AUTOSAR XML (schema 00046)
package /VehicleProject
  system System
package /NM
  nm config NmConfig: can-nm-cluster-coupling=coupled-cluster=[DBCNetWork_CAN, DBCNetWork_Can0_CAN]
    can nm cluster DBCNetWork_CAN: communication-cluster=DBCNetWork, nm-channel-id=0, nm-network-timeout=2, nm-user-data-length=6, nm-wait-bus-sleep-time=2
      can nm node XB_SUP_A: controller=CT_DBCNetWork, nm-if-ecu=XB_SUP_A_CAN, nm-node-id=1, rx-nm-pdu=Meg_NmRx_oDBCNetWork, tx-nm-pdu=Meg_NmTx_oDBCNetWork, nm-range-config={lower-can-id=1536, upper-can-id=1791}
      can nm node XB_SUP_B: nm-if-ecu=XB_SUP_B_CAN, nm-node-id=0, rx-nm-pdu=Meg_NmTx_oDBCNetWork, tx-nm-pdu=Meg_NmRx_oDBCNetWork, nm-range-config={lower-can-id=1536, upper-can-id=1791}
      can nm node XB_SUP_C: nm-if-ecu=XB_SUP_C_CAN, nm-node-id=0, nm-passive-mode-enabled=true, nm-range-config={lower-can-id=1536, upper-can-id=1791}
    can nm cluster DBCNetWork_Can0_CAN: communication-cluster=DBCNetWork_Can0, nm-channel-id=1, nm-network-timeout=2, nm-user-data-length=6, nm-wait-bus-sleep-time=2
      can nm node Host: nm-if-ecu=Host_CAN, nm-node-id=0, nm-passive-mode-enabled=true, nm-range-config={lower-can-id=1536, upper-can-id=1791}
      can nm node XB_SUP_A: controller=CT_DBCNetWork_Can0, nm-if-ecu=XB_SUP_A_CAN, nm-node-id=1, nm-passive-mode-enabled=true, nm-range-config={lower-can-id=1536, upper-can-id=1791}
    nm-if-ecus:
      4 x nm ecu, all with nm-node-id-enabled=true, nm-user-data-enabled=true:
        Host_CAN: nm-passive-mode-enabled=true
        XB_SUP_A_CAN: ecu-instance=XB_SUP_A, nm-passive-mode-enabled=true
        XB_SUP_B_CAN
        XB_SUP_C_CAN: nm-passive-mode-enabled=true
package /TP
  can tp config DBCNetWork_CAN: communication-cluster=DBCNetWork, can-tp-ecu{cycle-time-main-function=0.005, ecu-instance=XB_SUP_A}
    can tp channel TPCH: channel-id=0, channel-mode=FULL-DUPLEX-MODE
    can-tp-connection addressing-format=STANDARD, can-tp-channel=TPCH, data-pdu=Meg_FunDiag_Tp_oDBCNetWork, receiver=TN_XB_SUP_A, ta-type=FUNCTIONAL, tp-sdu=Meg_FunDiag_oDBCNetWork, transmitter=TN_XB_SUP_B:
      ident Meg_FunDiag_oTN_XB_SUP_B
    can-tp-connection addressing-format=STANDARD, can-tp-channel=TPCH, data-pdu=Meg_PhyDiag_Tp_oDBCNetWork, flow-control-pdu=Meg_ResDiag_Tp_oDBCNetWork, receiver=TN_XB_SUP_A, ta-type=PHYSICAL, tp-sdu=Meg_PhyDiag_oDBCNetWork, transmitter=TN_XB_SUP_B:
      ident Meg_PhyDiag_oTN_XB_SUP_A
    can-tp-connection addressing-format=STANDARD, can-tp-channel=TPCH, data-pdu=Meg_ResDiag_Tp_oDBCNetWork, flow-control-pdu=Meg_PhyDiag_Tp_oDBCNetWork, receiver=TN_XB_SUP_B, ta-type=PHYSICAL, tp-sdu=Meg_ResDiag_oDBCNetWork, transmitter=TN_XB_SUP_A:
      ident Meg_ResDiag_oTN_XB_SUP_A
    can tp node TN_XB_SUP_A: connector=CN_DBCNetWork
    can tp node TN_XB_SUP_B
package /Cluster
  can cluster DBCNetWork: baudrate=500000, protocol-name=CAN  # Vector_XWXZ_CAN1
    can physical channel CHNL: comm-connectors=CN_DBCNetWork
      frame Meg_FunDiag_oDBCNetWork: id 0x7DF, to XB_SUP_A, frame-length=8, can-addressing-mode=STANDARD
        n pdu Meg_FunDiag_Tp_oDBCNetWork: length=8
      frame Meg_NmRx_oDBCNetWork: id 0x600, to XB_SUP_A, frame-length=8, can-addressing-mode=STANDARD
        nm pdu Meg_NmRx_oDBCNetWork: length=8, unused-bit-pattern=0
      frame Meg_NmTx_oDBCNetWork: id 0x601, from XB_SUP_A, frame-length=8, can-addressing-mode=STANDARD
        nm pdu Meg_NmTx_oDBCNetWork: length=8, unused-bit-pattern=0
      frame Meg_PhyDiag_oDBCNetWork: id 0x701, to XB_SUP_A, frame-length=8, can-addressing-mode=STANDARD
        n pdu Meg_PhyDiag_Tp_oDBCNetWork: length=8
      frame Meg_ResDiag_oDBCNetWork: id 0x751, from XB_SUP_A, frame-length=8, can-addressing-mode=STANDARD
        n pdu Meg_ResDiag_Tp_oDBCNetWork: length=8
      frame Route_Can0ToCan1_100ms_oDBCNetWork: id 0x569, from XB_SUP_A, frame-length=8, can-addressing-mode=STANDARD
        user defined pdu Route_Can0ToCan1_100ms_oDBCNetWork: length=8
      frame Route_Can1ToCan0_100ms_oDBCNetWork: id 0x3AD, to XB_SUP_A, frame-length=8, can-addressing-mode=STANDARD
        user defined pdu Route_Can1ToCan0_100ms_oDBCNetWork: length=8
      frame SupA_Angle_oDBCNetWork: id 0x113, from XB_SUP_A, frame-length=8, can-addressing-mode=STANDARD
        pdu SupA_Angle_oDBCNetWork: length=8, minimum-delay=0, transmission-mode-false-timing=cyclic-timing={time-offset=0, time-period=0.01}, transmission-mode-true-timing=cyclic-timing={time-offset=0, time-period=0.01}, unused-bit-pattern=0
          signal AAA_Angle_oSupA_Angle_oDBCNetWork: start 5, 6 bit, big-endian, init-value=20, base-type=uint8, compu-method=CM_AAA_Angle, unit=U_o, transfer-property=PENDING
          mapping SG_Sig_Grp_0x113: i-signal-group=SG_Sig_Grp_0x113_oSupA_Angle_oDBCNetWork, transfer-property=PENDING
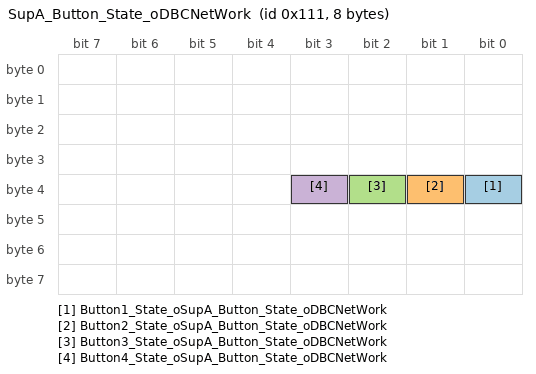
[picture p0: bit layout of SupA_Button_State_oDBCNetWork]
      frame SupA_Button_State_oDBCNetWork: id 0x111, from XB_SUP_A, frame-length=8, can-addressing-mode=STANDARD
        pdu SupA_Button_State_oDBCNetWork: length=8, minimum-delay=0, transmission-mode-false-timing=cyclic-timing={time-offset=0, time-period=0.01}, transmission-mode-true-timing=cyclic-timing={time-offset=0, time-period=0.01}, unused-bit-pattern=0
          signal Button1_State_oSupA_Button_State_oDBCNetWork: start 32, 1 bit, big-endian, init-value=0, base-type=boolean, compu-method=CM_Button1_State, transfer-property=PENDING
          signal Button2_State_oSupA_Button_State_oDBCNetWork: start 33, 1 bit, big-endian, init-value=0, base-type=boolean, compu-method=CM_Button2_State, transfer-property=PENDING
          signal Button3_State_oSupA_Button_State_oDBCNetWork: start 34, 1 bit, big-endian, init-value=0, base-type=boolean, compu-method=CM_Button3_State, transfer-property=PENDING
          signal Button4_State_oSupA_Button_State_oDBCNetWork: start 35, 1 bit, big-endian, init-value=0, base-type=boolean, compu-method=CM_Button4_State, transfer-property=PENDING
          mapping SG_Sig_Grp_0x111: i-signal-group=SG_Sig_Grp_0x111_oSupA_Button_State_oDBCNetWork, transfer-property=PENDING
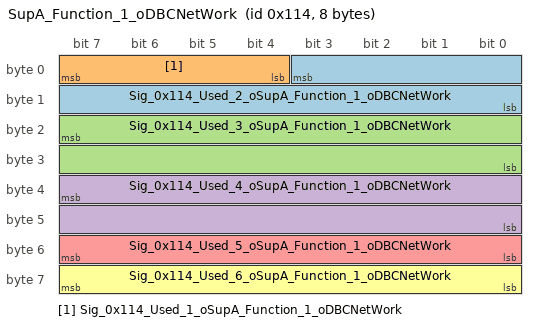
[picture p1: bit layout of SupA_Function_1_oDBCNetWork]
      frame SupA_Function_1_oDBCNetWork: id 0x114, from XB_SUP_A, frame-length=8, can-addressing-mode=STANDARD
        pdu SupA_Function_1_oDBCNetWork: length=8, minimum-delay=0, transmission-mode-false-timing={cyclic-timing={time-offset=0, time-period=0}, event-controlled-timing={number-of-repetitions=4, repetition-period=0.02}}, transmission-mode-true-timing={cyclic-timing={time-offset=0, time-period=0}, event-controlled-timing={number-of-repetitions=4, repetition-period=0.02}}, unused-bit-pattern=0
          signal Sig_0x114_Used_2_oSupA_Function_1_oDBCNetWork: start 3, 12 bit, big-endian, init-value=0, base-type=uint16, compu-method=CM_Sig_0x114_Used_2, data-constr=DC_Sig_0x114_Used_2, transfer-property=PENDING
          signal Sig_0x114_Used_1_oSupA_Function_1_oDBCNetWork: start 7, 4 bit, big-endian, init-value=0, base-type=uint8, compu-method=CM_Sig_0x114_Used_1, data-constr=DC_Sig_0x114_Used_1, transfer-property=PENDING
          signal Sig_0x114_Used_3_oSupA_Function_1_oDBCNetWork: start 23, 16 bit, big-endian, init-value=0, base-type=uint16, compu-method=CM_Sig_0x114_Used_3, data-constr=DC_Sig_0x114_Used_3, transfer-property=PENDING
          signal Sig_0x114_Used_4_oSupA_Function_1_oDBCNetWork: start 39, 16 bit, big-endian, init-value=0, base-type=uint16, compu-method=CM_Sig_0x114_Used_4, data-constr=DC_Sig_0x114_Used_4, transfer-property=PENDING
          signal Sig_0x114_Used_5_oSupA_Function_1_oDBCNetWork: start 55, 8 bit, big-endian, init-value=0, base-type=uint8, compu-method=CM_Sig_0x114_Used_5, data-constr=DC_Sig_0x114_Used_5, transfer-property=PENDING
          signal Sig_0x114_Used_6_oSupA_Function_1_oDBCNetWork: start 63, 8 bit, big-endian, init-value=0, base-type=uint8, compu-method=CM_Sig_0x114_Used_6, data-constr=DC_Sig_0x114_Used_6, transfer-property=TRIGGERED
          mapping SG_Sig_Grp_0x114: i-signal-group=SG_Sig_Grp_0x114_oSupA_Function_1_oDBCNetWork, transfer-property=PENDING
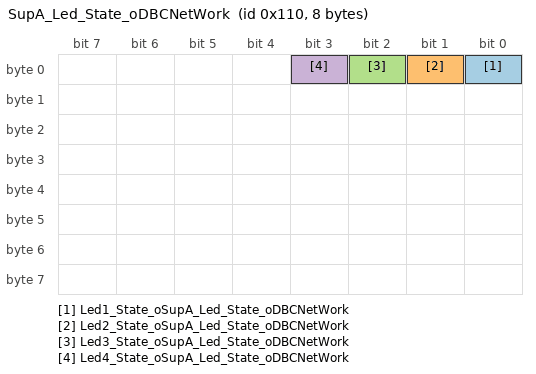
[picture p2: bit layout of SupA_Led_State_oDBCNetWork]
      frame SupA_Led_State_oDBCNetWork: id 0x110, from XB_SUP_A, frame-length=8, can-addressing-mode=STANDARD
        pdu SupA_Led_State_oDBCNetWork: length=8, minimum-delay=0, transmission-mode-false-timing=cyclic-timing={time-offset=0, time-period=0.01}, transmission-mode-true-timing=cyclic-timing={time-offset=0, time-period=0.01}, unused-bit-pattern=0
          signal Led1_State_oSupA_Led_State_oDBCNetWork: start 0, 1 bit, big-endian, init-value=0, base-type=boolean, compu-method=CM_Led1_State, transfer-property=PENDING
          signal Led2_State_oSupA_Led_State_oDBCNetWork: start 1, 1 bit, big-endian, init-value=0, base-type=boolean, compu-method=CM_Led2_State, transfer-property=PENDING
          signal Led3_State_oSupA_Led_State_oDBCNetWork: start 2, 1 bit, big-endian, init-value=0, base-type=boolean, compu-method=CM_Led3_State, transfer-property=PENDING
          signal Led4_State_oSupA_Led_State_oDBCNetWork: start 3, 1 bit, big-endian, init-value=0, base-type=boolean, compu-method=CM_Led4_State, transfer-property=PENDING
          mapping SG_Sig_Grp_0x110: i-signal-group=SG_Sig_Grp_0x110_oSupA_Led_State_oDBCNetWork, transfer-property=PENDING
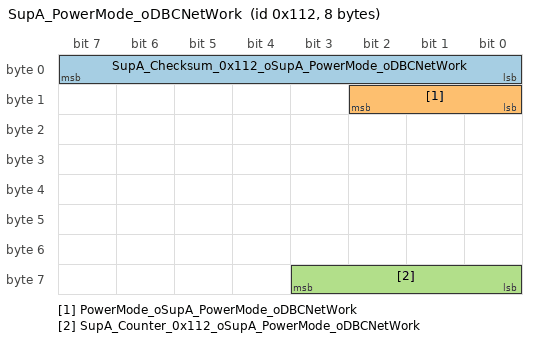
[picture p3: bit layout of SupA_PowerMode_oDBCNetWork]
      frame SupA_PowerMode_oDBCNetWork: id 0x112, from XB_SUP_A, frame-length=8, can-addressing-mode=STANDARD
        pdu SupA_PowerMode_oDBCNetWork: length=8, minimum-delay=0, transmission-mode-false-timing=cyclic-timing={time-offset=0, time-period=0.2}, transmission-mode-true-timing=cyclic-timing={time-offset=0, time-period=0.2}, unused-bit-pattern=0
          signal SupA_Checksum_0x112_oSupA_PowerMode_oDBCNetWork: start 7, 8 bit, big-endian, init-value=0, base-type=uint8, compu-method=CM_SupA_Checksum_0x112, data-constr=DC_SupA_Checksum_0x112, transfer-property=PENDING
          signal PowerMode_oSupA_PowerMode_oDBCNetWork: start 10, 3 bit, big-endian, init-value=0, base-type=uint8, compu-method=CM_PowerMode, data-constr=DC_PowerMode, transfer-property=PENDING
          signal SupA_Counter_0x112_oSupA_PowerMode_oDBCNetWork: start 59, 4 bit, big-endian, init-value=0, base-type=uint8, compu-method=CM_SupA_Counter_0x112, data-constr=DC_SupA_Counter_0x112, transfer-property=PENDING
          mapping SG_Sig_Grp_0x112: i-signal-group=SG_Sig_Grp_0x112_oSupA_PowerMode_oDBCNetWork, transfer-property=PENDING
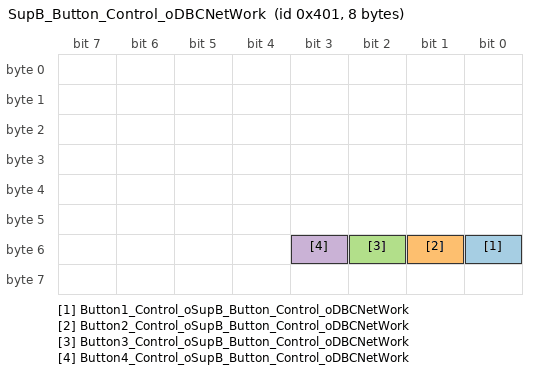
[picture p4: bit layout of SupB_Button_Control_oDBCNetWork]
      frame SupB_Button_Control_oDBCNetWork: id 0x401, to XB_SUP_A, frame-length=8, can-addressing-mode=STANDARD
        pdu SupB_Button_Control_oDBCNetWork: length=8, minimum-delay=0, transmission-mode-false-timing=cyclic-timing={time-offset=0, time-period=0.01}, transmission-mode-true-timing=cyclic-timing={time-offset=0, time-period=0.01}, unused-bit-pattern=0
          signal Button1_Control_oSupB_Button_Control_oDBCNetWork: start 48, 1 bit, big-endian, init-value=0, base-type=boolean, compu-method=CM_Button1_Control, transfer-property=PENDING, to XB_SUP_A
          signal Button2_Control_oSupB_Button_Control_oDBCNetWork: start 49, 1 bit, big-endian, init-value=0, base-type=boolean, compu-method=CM_Button2_Control, transfer-property=PENDING, to XB_SUP_A
          signal Button3_Control_oSupB_Button_Control_oDBCNetWork: start 50, 1 bit, big-endian, init-value=0, base-type=boolean, compu-method=CM_Button3_Control, transfer-property=PENDING, to XB_SUP_A
          signal Button4_Control_oSupB_Button_Control_oDBCNetWork: start 51, 1 bit, big-endian, init-value=0, base-type=boolean, compu-method=CM_Button4_Control, transfer-property=PENDING, to XB_SUP_A
          mapping SG_Sig_Grp_0x401: i-signal-group=SG_Sig_Grp_0x401_oSupB_Button_Control_oDBCNetWork, transfer-property=PENDING
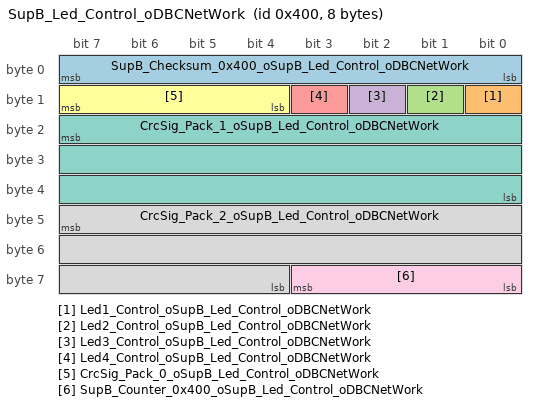
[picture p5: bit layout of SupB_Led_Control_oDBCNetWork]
      frame SupB_Led_Control_oDBCNetWork: id 0x400, to XB_SUP_A, frame-length=8, can-addressing-mode=STANDARD
        pdu SupB_Led_Control_oDBCNetWork: length=8, minimum-delay=0, transmission-mode-false-timing=cyclic-timing={time-offset=0, time-period=0.01}, transmission-mode-true-timing=cyclic-timing={time-offset=0, time-period=0.01}, unused-bit-pattern=0
          signal SupB_Checksum_0x400_oSupB_Led_Control_oDBCNetWork: start 7, 8 bit, big-endian, init-value=0, base-type=uint8, compu-method=CM_SupB_Checksum_0x400, data-constr=DC_SupB_Checksum_0x400, transfer-property=PENDING, to XB_SUP_A
          signal Led1_Control_oSupB_Led_Control_oDBCNetWork: start 8, 1 bit, big-endian, init-value=1, base-type=boolean, compu-method=CM_Led1_Control, data-constr=DC_Led1_Control, transfer-property=PENDING, to XB_SUP_A
          signal Led2_Control_oSupB_Led_Control_oDBCNetWork: start 9, 1 bit, big-endian, init-value=1, base-type=boolean, compu-method=CM_Led2_Control, data-constr=DC_Led2_Control, transfer-property=PENDING, to XB_SUP_A
          signal Led3_Control_oSupB_Led_Control_oDBCNetWork: start 10, 1 bit, big-endian, init-value=1, base-type=boolean, compu-method=CM_Led3_Control, data-constr=DC_Led3_Control, transfer-property=PENDING, to XB_SUP_A
          signal Led4_Control_oSupB_Led_Control_oDBCNetWork: start 11, 1 bit, big-endian, init-value=1, base-type=boolean, compu-method=CM_Led4_Control, data-constr=DC_Led4_Control, transfer-property=PENDING, to XB_SUP_A
          signal CrcSig_Pack_0_oSupB_Led_Control_oDBCNetWork: start 15, 4 bit, big-endian, init-value=0, base-type=uint8, compu-method=CM_CrcSig_Pack_0, data-constr=DC_CrcSig_Pack_0, transfer-property=PENDING, to XB_SUP_A
          signal CrcSig_Pack_1_oSupB_Led_Control_oDBCNetWork: start 23, 24 bit, big-endian, init-value=0, base-type=uint32, compu-method=CM_CrcSig_Pack_1, data-constr=DC_CrcSig_Pack_1, transfer-property=PENDING, to XB_SUP_A
          signal CrcSig_Pack_2_oSupB_Led_Control_oDBCNetWork: start 47, 20 bit, big-endian, init-value=0, base-type=uint32, compu-method=CM_CrcSig_Pack_2, data-constr=DC_CrcSig_Pack_2, transfer-property=PENDING, to XB_SUP_A
          signal SupB_Counter_0x400_oSupB_Led_Control_oDBCNetWork: start 59, 4 bit, big-endian, init-value=0, base-type=uint8, compu-method=CM_SupB_Counter_0x400, data-constr=DC_SupB_Counter_0x400, transfer-property=PENDING, to XB_SUP_A
          mapping SG_Sig_Grp_0x400: i-signal-group=SG_Sig_Grp_0x400_oSupB_Led_Control_oDBCNetWork, transfer-property=PENDING
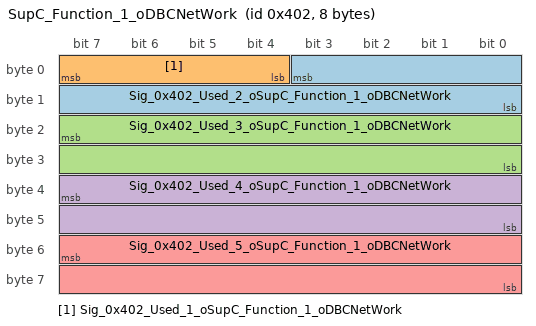
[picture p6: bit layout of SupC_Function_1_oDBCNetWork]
      frame SupC_Function_1_oDBCNetWork: id 0x402, to XB_SUP_A, frame-length=8, can-addressing-mode=STANDARD
        pdu SupC_Function_1_oDBCNetWork: length=8, minimum-delay=0, transmission-mode-false-timing=cyclic-timing={time-offset=0, time-period=0.01}, transmission-mode-true-timing=cyclic-timing={time-offset=0, time-period=0.01}, unused-bit-pattern=0
          signal Sig_0x402_Used_2_oSupC_Function_1_oDBCNetWork: start 3, 12 bit, big-endian, init-value=0, base-type=uint16, compu-method=CM_Sig_0x402_Used_2, data-constr=DC_Sig_0x402_Used_2, transfer-property=PENDING, to XB_SUP_A
          signal Sig_0x402_Used_1_oSupC_Function_1_oDBCNetWork: start 7, 4 bit, big-endian, init-value=0, base-type=uint8, compu-method=CM_Sig_0x402_Used_1, data-constr=DC_Sig_0x402_Used_1, transfer-property=PENDING, to XB_SUP_A
          signal Sig_0x402_Used_3_oSupC_Function_1_oDBCNetWork: start 23, 16 bit, big-endian, init-value=0, base-type=uint16, compu-method=CM_Sig_0x402_Used_3, data-constr=DC_Sig_0x402_Used_3, transfer-property=PENDING, to XB_SUP_A
          signal Sig_0x402_Used_4_oSupC_Function_1_oDBCNetWork: start 39, 16 bit, big-endian, init-value=0, base-type=uint16, compu-method=CM_Sig_0x402_Used_4, data-constr=DC_Sig_0x402_Used_4, transfer-property=PENDING, to XB_SUP_A
          signal Sig_0x402_Used_5_oSupC_Function_1_oDBCNetWork: start 55, 16 bit, big-endian, init-value=0, base-type=uint16, compu-method=CM_Sig_0x402_Used_5, data-constr=DC_Sig_0x402_Used_5, transfer-property=PENDING, to XB_SUP_A
          mapping SG_Sig_Grp_0x402: i-signal-group=SG_Sig_Grp_0x402_oSupC_Function_1_oDBCNetWork, transfer-property=PENDING
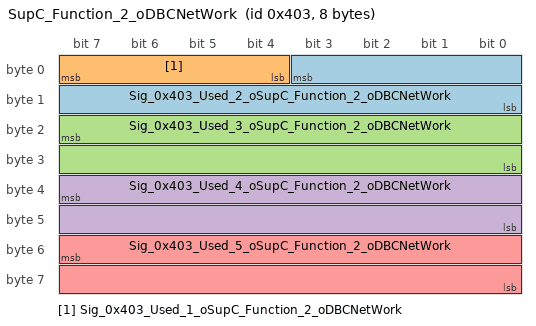
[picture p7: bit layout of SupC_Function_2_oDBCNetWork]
      frame SupC_Function_2_oDBCNetWork: id 0x403, to XB_SUP_A, frame-length=8, can-addressing-mode=STANDARD
        pdu SupC_Function_2_oDBCNetWork: length=8, minimum-delay=0, transmission-mode-false-timing=cyclic-timing={time-offset=0, time-period=0.01}, transmission-mode-true-timing=cyclic-timing={time-offset=0, time-period=0.01}, unused-bit-pattern=0
          signal Sig_0x403_Used_2_oSupC_Function_2_oDBCNetWork: start 3, 12 bit, big-endian, init-value=0, base-type=uint16, compu-method=CM_Sig_0x403_Used_2, data-constr=DC_Sig_0x403_Used_2, transfer-property=PENDING, to XB_SUP_A
          signal Sig_0x403_Used_1_oSupC_Function_2_oDBCNetWork: start 7, 4 bit, big-endian, init-value=0, base-type=uint8, compu-method=CM_Sig_0x403_Used_1, data-constr=DC_Sig_0x403_Used_1, transfer-property=PENDING, to XB_SUP_A
          signal Sig_0x403_Used_3_oSupC_Function_2_oDBCNetWork: start 23, 16 bit, big-endian, init-value=0, base-type=uint16, compu-method=CM_Sig_0x403_Used_3, data-constr=DC_Sig_0x403_Used_3, transfer-property=PENDING, to XB_SUP_A
          signal Sig_0x403_Used_4_oSupC_Function_2_oDBCNetWork: start 39, 16 bit, big-endian, init-value=0, base-type=uint16, compu-method=CM_Sig_0x403_Used_4, data-constr=DC_Sig_0x403_Used_4, transfer-property=PENDING, to XB_SUP_A
          signal Sig_0x403_Used_5_oSupC_Function_2_oDBCNetWork: start 55, 16 bit, big-endian, init-value=0, base-type=uint16, compu-method=CM_Sig_0x403_Used_5, data-constr=DC_Sig_0x403_Used_5, transfer-property=PENDING, to XB_SUP_A
          mapping SG_Sig_Grp_0x403: i-signal-group=SG_Sig_Grp_0x403_oSupC_Function_2_oDBCNetWork, transfer-property=PENDING
      pdu triggering PT_Meg_FunDiag: pdu=Meg_FunDiag_oDBCNetWork, to XB_SUP_A
      pdu triggering PT_Meg_PhyDiag: pdu=Meg_PhyDiag_oDBCNetWork, to XB_SUP_A
      pdu triggering PT_Meg_ResDiag: pdu=Meg_ResDiag_oDBCNetWork, from XB_SUP_A
  can cluster DBCNetWork_Can0: baudrate=500000, protocol-name=CAN  # Vector_XWXZ_CAN0
    can physical channel CHNL: comm-connectors=CN_DBCNetWork_Can0
      frame Ecu_Receive_Msg_oDBCNetWork_Can0: id 0x200, to XB_SUP_A, frame-length=8, can-addressing-mode=STANDARD
        user defined pdu Ecu_Receive_Msg_oDBCNetWork_Can0: length=8
      frame Ecu_Send_Msg_oDBCNetWork_Can0: id 0x100, from XB_SUP_A, frame-length=8, can-addressing-mode=STANDARD
        user defined pdu Ecu_Send_Msg_oDBCNetWork_Can0: length=8
      frame Rout_Can0ToCan1_100ms_oDBCNetWork_Can0: id 0x569, to XB_SUP_A, frame-length=8, can-addressing-mode=STANDARD
        user defined pdu Rout_Can0ToCan1_100ms_oDBCNetWork_Can0: length=8
      frame Rout_Can1ToCan0_100ms_oDBCNetWork_Can0: id 0x3AD, from XB_SUP_A, frame-length=8, can-addressing-mode=STANDARD
        user defined pdu Rout_Can1ToCan0_100ms_oDBCNetWork_Can0: length=8
package /ECU
  ecu instance XB_SUP_A: associated-com-i-pdu-group=[XB_SUP_A_oDBCNetWork_Rx, XB_SUP_A_oDBCNetWork_Tx]
    can communication controller CT_DBCNetWork: can-controller-attributes=can-controller-configuration-requirements={max-number-of-time-quanta-per-bit=20, max-sample-point=1, max-sync-jump-width=20, min-number-of-time-quanta-per-bit=10, min-sample-point=1, min-sync-jump-width=20}
    can communication controller CT_DBCNetWork_Can0: can-controller-attributes=can-controller-configuration-requirements={max-number-of-time-quanta-per-bit=20, max-sample-point=1, max-sync-jump-width=20, min-number-of-time-quanta-per-bit=10, min-sample-point=1, min-sync-jump-width=20}
    can communication connector CN_DBCNetWork: comm-controller=CT_DBCNetWork
    can communication connector CN_DBCNetWork_Can0: comm-controller=CT_DBCNetWork_Can0
package /Gateway
  gateway XB_SUP_A: ecu=XB_SUP_A
package /IPDUGroup
  i signal i pdu group XB_SUP_A_oDBCNetWork_Rx: communication-direction=IN
    i-signal-i-pdus:
      SupB_Button_Control_oDBCNetWork
      SupB_Led_Control_oDBCNetWork
      SupC_Function_1_oDBCNetWork
      SupC_Function_2_oDBCNetWork
  i signal i pdu group XB_SUP_A_oDBCNetWork_Tx: communication-direction=OUT
    i-signal-i-pdus:
      SupA_Angle_oDBCNetWork
      SupA_Button_State_oDBCNetWork
      SupA_Function_1_oDBCNetWork
      SupA_Led_State_oDBCNetWork
      SupA_PowerMode_oDBCNetWork
package /PDU
  dcm i pdu Meg_FunDiag_oDBCNetWork: length=7, diag-pdu-type=DIAG-REQUEST
  dcm i pdu Meg_PhyDiag_oDBCNetWork: length=8, diag-pdu-type=DIAG-REQUEST
  dcm i pdu Meg_ResDiag_oDBCNetWork: length=8, diag-pdu-type=DIAG-RESPONSE
package /ISignal
  9 x i signal group:
    SG_Sig_Grp_0x110_oSupA_Led_State_oDBCNetWork: i-signal=[Led1_State_oSupA_Led_State_oDBCNetWork, Led2_State_oSupA_Led_State_oDBCNetWork, Led3_State_oSupA_Led_State_oDBCNetWork, Led4_State_oSupA_Led_State_oDBCNetWork], system-signal-group=SG_Sig_Grp_0x110
    SG_Sig_Grp_0x111_oSupA_Button_State_oDBCNetWork: i-signal=[Button1_State_oSupA_Button_State_oDBCNetWork, Button2_State_oSupA_Button_State_oDBCNetWork, Button3_State_oSupA_Button_State_oDBCNetWork, Button4_State_oSupA_Button_State_oDBCNetWork], system-signal-group=SG_Sig_Grp_0x111
    SG_Sig_Grp_0x112_oSupA_PowerMode_oDBCNetWork: i-signal=[PowerMode_oSupA_PowerMode_oDBCNetWork, SupA_Checksum_0x112_oSupA_PowerMode_oDBCNetWork, SupA_Counter_0x112_oSupA_PowerMode_oDBCNetWork], system-signal-group=SG_Sig_Grp_0x112
    SG_Sig_Grp_0x113_oSupA_Angle_oDBCNetWork: i-signal=AAA_Angle_oSupA_Angle_oDBCNetWork, system-signal-group=SG_Sig_Grp_0x113
    SG_Sig_Grp_0x114_oSupA_Function_1_oDBCNetWork: i-signal=[Sig_0x114_Used_1_oSupA_Function_1_oDBCNetWork, Sig_0x114_Used_2_oSupA_Function_1_oDBCNetWork, Sig_0x114_Used_3_oSupA_Function_1_oDBCNetWork, Sig_0x114_Used_4_oSupA_Function_1_oDBCNetWork, Sig_0x114_Used_5_oSupA_Function_1_oDBCNetWork], system-signal-group=SG_Sig_Grp_0x114
    SG_Sig_Grp_0x400_oSupB_Led_Control_oDBCNetWork: i-signal=[CrcSig_Pack_0_oSupB_Led_Control_oDBCNetWork, CrcSig_Pack_1_oSupB_Led_Control_oDBCNetWork, CrcSig_Pack_2_oSupB_Led_Control_oDBCNetWork, Led1_Control_oSupB_Led_Control_oDBCNetWork, Led2_Control_oSupB_Led_Control_oDBCNetWork, Led3_Control_oSupB_Led_Control_oDBCNetWork, Led4_Control_oSupB_Led_Control_oDBCNetWork, SupB_Checksum_0x400_oSupB_Led_Control_oDBCNetWork, SupB_Counter_0x400_oSupB_Led_Control_oDBCNetWork], system-signal-group=SG_Sig_Grp_0x400
    SG_Sig_Grp_0x401_oSupB_Button_Control_oDBCNetWork: i-signal=[Button1_Control_oSupB_Button_Control_oDBCNetWork, Button2_Control_oSupB_Button_Control_oDBCNetWork, Button3_Control_oSupB_Button_Control_oDBCNetWork, Button4_Control_oSupB_Button_Control_oDBCNetWork], system-signal-group=SG_Sig_Grp_0x401
    SG_Sig_Grp_0x402_oSupC_Function_1_oDBCNetWork: i-signal=[Sig_0x402_Used_1_oSupC_Function_1_oDBCNetWork, Sig_0x402_Used_2_oSupC_Function_1_oDBCNetWork, Sig_0x402_Used_3_oSupC_Function_1_oDBCNetWork, Sig_0x402_Used_4_oSupC_Function_1_oDBCNetWork, Sig_0x402_Used_5_oSupC_Function_1_oDBCNetWork], system-signal-group=SG_Sig_Grp_0x402
    SG_Sig_Grp_0x403_oSupC_Function_2_oDBCNetWork: i-signal=[Sig_0x403_Used_1_oSupC_Function_2_oDBCNetWork, Sig_0x403_Used_2_oSupC_Function_2_oDBCNetWork, Sig_0x403_Used_3_oSupC_Function_2_oDBCNetWork, Sig_0x403_Used_4_oSupC_Function_2_oDBCNetWork, Sig_0x403_Used_5_oSupC_Function_2_oDBCNetWork], system-signal-group=SG_Sig_Grp_0x403
